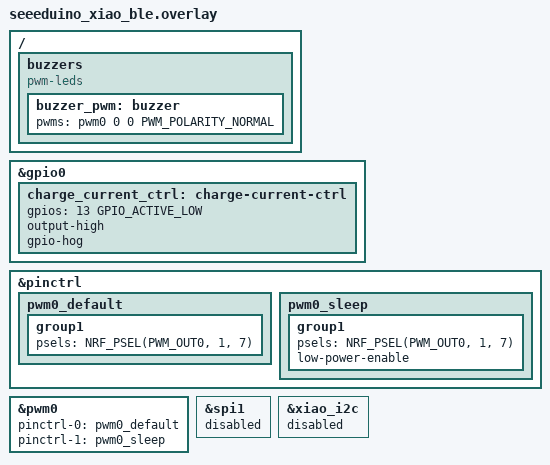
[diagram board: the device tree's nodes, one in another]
/*
 * Copyright (c) 2025 The ZMK Contributors
 * Copyright (c) 2025 monksoffunk
 *
 * SPDX-License-Identifier: MIT
 */

#include "seeeduino_xiao_ble-kscan.dtsi"

// Buzzer configuration for Xiao BLE plus
// RP2040 does not have enough pins for buzzer

// Charge current control for Xiao BLE plus
// GPIO0 13 controls fast charge mode (active-low)
&gpio0 {
    charge_current_ctrl: charge-current-ctrl {
        gpios = <13 GPIO_ACTIVE_LOW>;  // GPIO0 13 is active-low for fast charge mode (100mA)
        output-high;                     // Set normal charge mode (50mA)
        gpio-hog;
    };
};

/ {
    buzzers {
        compatible = "pwm-leds";
        buzzer_pwm: buzzer {
            pwms = <&pwm0 0 0 PWM_POLARITY_NORMAL>;
        };
    };
};

&pinctrl {
    pwm0_default: pwm0_default {
        group1 {
            psels = <NRF_PSEL(PWM_OUT0, 1, 7)>;
        };
    };

    pwm0_sleep: pwm0_sleep {
        group1 {
            psels = <NRF_PSEL(PWM_OUT0, 1, 7)>;
            low-power-enable;
        };
    };
};

&pwm0 {
    status = "okay";
    pinctrl-0 = <&pwm0_default>;
    pinctrl-1 = <&pwm0_sleep>;
    pinctrl-names = "default", "sleep";
};

// Disable unused peripherals to avoid conflicts
&spi1 {
    status = "disabled";
};

&xiao_i2c {
    status = "disabled";
};

